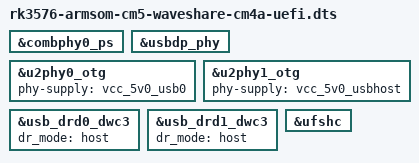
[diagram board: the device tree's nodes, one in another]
// SPDX-License-Identifier: (GPL-2.0+ OR MIT)
/*
 * Waveshare CM4-IO-BASE-A — UEFI mainline FDT overlay
 *
 * Extends rk3576-armsom-cm5-waveshare-cm4a.dts with nodes that may not yet be in the
 * upstream kernel but are required for a fully-featured UEFI-booted system:
 *   - ComboPHY0 (USB3 lane; here used for PCIe to drive M.2 slot)
 *     NOTE: When PcdComboPhy0Mode = PCIE (default), ComboPHY0 drives PCIe.
 *           When switched to USB3, it drives USBDP PHY for DRD0 SS lane
 *           (the USB adapter connector on the carrier side).
 *           This overlay enables both for maximum Linux compatibility;
 *           only one will actually be active at runtime based on CRU mux.
 *   - USB-DP PHY (SuperSpeed for DRD0 USB adapter connector)
 *   - USB2 OTG PHY ports (DRD0 and DRD1 host-mode supplies)
 *   - DRD0 DWC3 configured as host
 *   - DRD1 DWC3 host mode (combphy1_psu USB3 + u2phy1 HS)
 *   - UFS host controller
 *
 * Copyright (c) 2025, Waveshare CM4-IO-BASE-A EDK2 Port
 */

#include "rk3576-armsom-cm5-waveshare-cm4a.dts"

/*
 * combphy0_ps: PCIe lane for M.2 slot (primary function on BASE-A).
 * The base DTS already has combphy0_ps = okay; harmless to repeat.
 */
&combphy0_ps {
	status = "okay";
};

/*
 * USB-DP PHY — provides USB3 SuperSpeed lane to the USB adapter connector (DRD0).
 * Required for SuperSpeed enumeration on the USB3/4 adapter connector.
 */
&usbdp_phy {
	status = "okay";
};

/*
 * USB2 OTG sub-nodes: both ports driven as host.
 * DRD0 (USB adapter connector): u2phy0_otg with vcc_5v0_usb0 supply.
 * DRD1 (FE1.1S USB hub): u2phy1_otg with vcc_5v0_usbhost supply.
 */
&u2phy0_otg {
	phy-supply = <&vcc_5v0_usb0>;
	status = "okay";
};

&u2phy1_otg {
	phy-supply = <&vcc_5v0_usbhost>;
	status = "okay";
};

/*
 * DRD0 — USB adapter connector: force host mode for UEFI.
 */
&usb_drd0_dwc3 {
	dr_mode = "host";
	status = "okay";
};

/*
 * DRD1 — FE1.1S USB hub port: host mode (combphy1 SS + u2phy1 HS).
 */
&usb_drd1_dwc3 {
	dr_mode = "host";
	status = "okay";
};

/*
 * UFS host controller.
 * RK3576 silicon includes a UFS HC; enabling it allows the OS UFS driver
 * to probe even if no UFS device is physically connected.
 */
&ufshc {
	status = "okay";
};
